# STM32WB06 register map
File version: 1.0
Registers are 32-bit, read-write, reset 0x0 unless marked. A register's access mark holds for its fields unless they carry their own. Offsets are from the block's base; [hi:lo] are bit positions; {n}, {i} and the like mark numbered series.

## SPI1
Base 0x41002000
Same registers: SPI2 0x41003000, SPI3 0x41007000
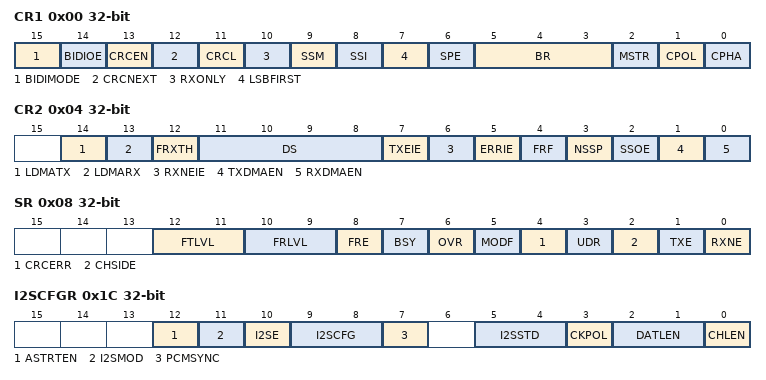
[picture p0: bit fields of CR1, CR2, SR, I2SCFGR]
0x00 CR1
  [15] BIDIMODE
  [14] BIDIOE
  [13] CRCEN
  [12] CRCNEXT
  [11] CRCL
    0=CRC_8BIT (8-bit CRC length); 1=CRC_16BIT (16-bit CRC length)
  [10] RXONLY
  [9] SSM
  [8] SSI
  [7] LSBFIRST
    1=LSB_FIRST (Data is transmitted/received with the LSB first); 0=MSB_FIRST (Data is transmitted/received with the MSB first)
  [6] SPE
  [5:3] BR
    0=DIV2 (BaudRate control equal to fPCLK/2); 1=DIV4 (BaudRate control equal to fPCLK/4); 2=DIV8 (BaudRate control equal to fPCLK/8); 3=DIV16 (BaudRate control equal to fPCLK/16); 4=DIV32 (BaudRate control equal to fPCLK/32); 5=DIV64 (BaudRate control equal to fPCLK/64); 6=DIV128 (BaudRate control equal to fPCLK/128); 7=DIV256 (BaudRate control equal to fPCLK/256)
  [2] MSTR
  [1] CPOL
    0=LOW (Clock to 0 when idle); 1=HIGH (Clock to 1 when idle)
  [0] CPHA
    0=PHASE_1EDGE (First clock transition is the first data capture edge); 1=PHASE_2EDGE (Second clock transition is the first data capture edge)
0x04 CR2
  [14] LDMATX
  [13] LDMARX
  [12] FRXTH
    0=HALF (RXNE event is generated if FIFO level is greater than or equal to 1/2 (16-bit)); 1=QUARTER (RXNE event is generated if FIFO level is greater than or equal to 1/4 (8-bit))
  [11:8] DS
    {v}=DATAWIDTH_{v+1}BIT (Data length for SPI transfer: {v+1} bits) (v=3..15)
  [7] TXEIE
  [6] RXNEIE
  [5] ERRIE
  [4] FRF
    0=MOTOROLA (Motorola mode. Used as default value); 1=TI (TI mode)
  [3] NSSP
  [2] SSOE
  [1] TXDMAEN
  [0] RXDMAEN
0x08 SR
  [12:11] FTLVL
    0=EMPTY (FIFO transmission empty); 1=QUARTER_FULL (FIFO transmission 1/4); 2=HALF_FULL (FIFO transmission 1/2); 3=FULL (FIFO transmission full)
  [10:9] FRLVL
    0=EMPTY (FIFO reception empty); 1=QUARTER_FULL (FIFO reception 1/4); 2=HALF_FULL (FIFO reception 1/2); 3=FULL (FIFO reception full)
  [8] FRE
  [7] BSY
  [6] OVR
  [5] MODF
  [4] CRCERR
  [3] UDR
  [2] CHSIDE
  [1] TXE
  [0] RXNE
0x0C DR
  [15:0] DR
0x10 CRCPR
  [15:0] CRCPOLY
0x14 RXCRCR
  [15:0] RXCRC
0x18 TXCRCR
  [15:0] TXCRC
0x1C I2SCFGR
  [12] ASTRTEN
  [11] I2SMOD
  [10] I2SE
  [9:8] I2SCFG
    0=SLAVE_TX (Slave Tx configuration); 1=SLAVE_RX (Slave Rx configuration); 2=MASTER_TX (Master Tx configuration); 3=MASTER_RX (Master Rx configuration)
  [7] PCMSYNC
  [5:4] I2SSTD
  [3] CKPOL
    0=LOW (Clock steady state is low level); 1=HIGH (Clock steady state is high level)
  [2:1] DATLEN
  [0] CHLEN
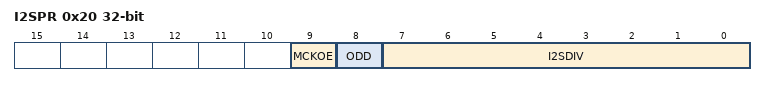
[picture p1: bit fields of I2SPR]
0x20 I2SPR
  [9] MCKOE, [8] ODD, [7:0] I2SDIV

## LPUART1
Base 0x41005000
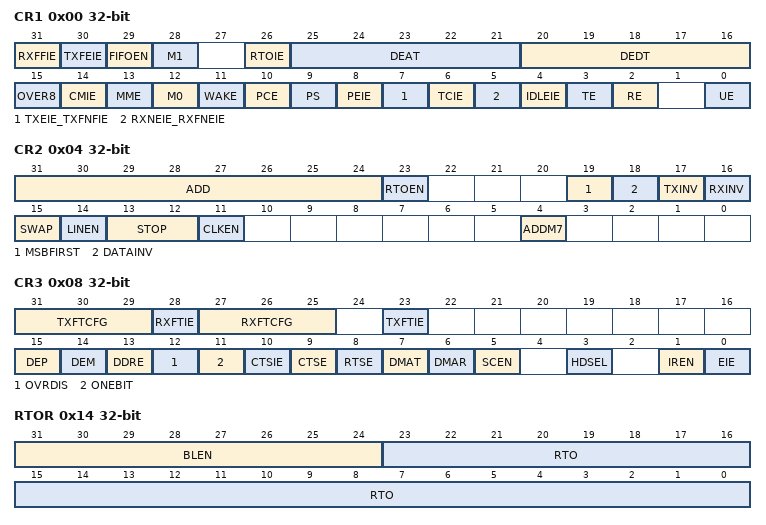
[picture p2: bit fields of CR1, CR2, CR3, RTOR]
0x00 CR1
  [31] RXFFIE
  [30] TXFEIE
  [29] FIFOEN
  [28] M1 — Word length - Bit 1
  [26] RTOIE
  [25:21] DEAT
  [20:16] DEDT
  [15] OVER8
    0=OVERSAMPLING_16 (Oversampling by 16); 1=OVERSAMPLING_8 (Oversampling by 8)
  [14] CMIE
  [13] MME
  [12] M0 — Word length - Bit 0
  [11] WAKE
    0=IDLELINE (LPUART wake up from Mute mode on Idle Line); 1=ADDRESSMARK (LPUART wake up from Mute mode on Address Mark)
  [10] PCE
  [9] PS
  [8] PEIE
  [7] TXEIE_TXFNFIE
  [6] TCIE
  [5] RXNEIE_RXFNEIE
  [4] IDLEIE
  [3] TE
  [2] RE
  [0] UE
0x04 CR2
  [31:24] ADD
  [23] RTOEN
  [19] MSBFIRST
    0=LSBFIRST; 1=MSBFIRST
  [18] DATAINV
    0=POSITIVE; 1=NEGATIVE
  [17] TXINV
    0=STANDARD (TX pin signal works using the standard logic levels); 1=INVERTED (TX pin signal values are inverted.)
  [16] RXINV
    0=STANDARD (RX pin signal works using the standard logic levels); 1=INVERTED (RX pin signal values are inverted.)
  [15] SWAP
    0=STANDARD (TX/RX pins are used as defined in standard pinout); 1=SWAPPED (TX and RX pins functions are swapped.)
  [14] LINEN
  [13:12] STOP
    0=STOPBITS_1 (1 stop bit); 2=STOPBITS_2 (2 stop bits); 1=STOPBITS_0_5 (0.5 stop bit); 3=STOPBITS_1_5 (1.5 stop bits)
  [11] CLKEN
  [4] ADDM7
    0=DETECT_4B (4-bit address detection method selected); 1=DETECT_7B (7-bit address detection (in 8-bit data mode) method selected)
0x08 CR3
  [31:29] TXFTCFG
  [28] RXFTIE
  [27:25] RXFTCFG
  [23] TXFTIE
  [15] DEP
    0=HIGH (DE signal is active high); 1=LOW (DE signal is active low)
  [14] DEM
  [13] DDRE
  [12] OVRDIS
  [11] ONEBIT
  [10] CTSIE
  [9] CTSE
  [8] RTSE
  [7] DMAT
  [6] DMAR
  [5] SCEN
  [3] HDSEL
  [1] IREN
  [0] EIE
0x0C BRR
  [19:0] BRR
0x14 RTOR
  [31:24] BLEN, [23:0] RTO
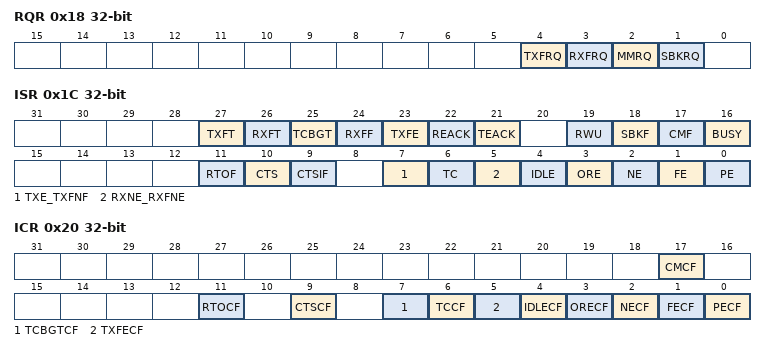
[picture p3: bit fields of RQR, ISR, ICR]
0x18 RQR
  [4] TXFRQ, [3] RXFRQ, [2] MMRQ, [1] SBKRQ
0x1C ISR
  [27] TXFT, [26] RXFT, [25] TCBGT, [24] RXFF, [23] TXFE, [22] REACK, [21] TEACK, [19] RWU, [18] SBKF, [17] CMF, [16] BUSY, [11] RTOF, [10] CTS, [9] CTSIF, [7] TXE_TXFNF, [6] TC, [5] RXNE_RXFNE, [4] IDLE, [3] ORE, [2] NE, [1] FE, [0] PE
0x20 ICR
  [17] CMCF, [11] RTOCF, [9] CTSCF, [7] TCBGTCF, [6] TCCF, [5] TXFECF, [4] IDLECF, [3] ORECF, [2] NECF, [1] FECF, [0] PECF
0x24 RDR
  [8:0] RDR
0x28 TDR
  [8:0] TDR
0x2C PRESC
  [3:0] PRESCALER
    0=DIV1 (Input clock not divided); 1=DIV2 (Input clock divided by 2); 2=DIV4 (Input clock divided by 4); 3=DIV6; 4=DIV8 (Input clock divided by 8); 5=DIV10; 6=DIV12; 7=DIV16; 8=DIV32 (Input clock divided by 32); 9=DIV64; 10=DIV128; 11=DIV256
